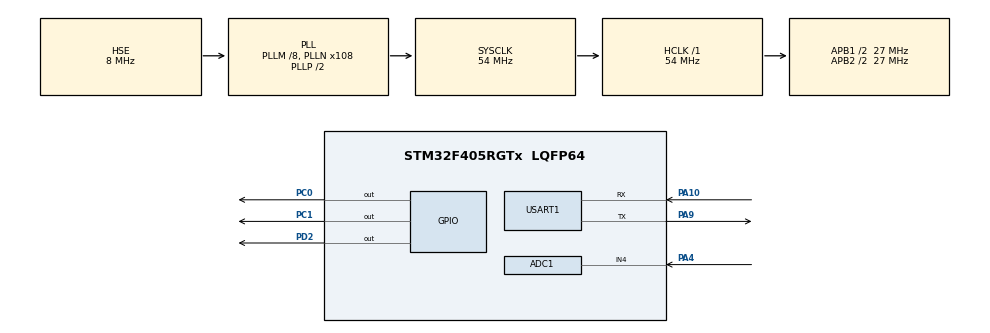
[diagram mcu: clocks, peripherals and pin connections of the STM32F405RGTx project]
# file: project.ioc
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ADC1.Channel-0\#ChannelRegularConversion=ADC_CHANNEL_4
ADC1.ContinuousConvMode=ENABLE
ADC1.DMAContinuousRequests=ENABLE
ADC1.NbrOfConversionFlag=1
ADC1.Rank-0\#ChannelRegularConversion=1
ADC1.SamplingTime-0\#ChannelRegularConversion=ADC_SAMPLETIME_112CYCLES
ADC1.master=1
Dma.ADC1.0.Direction=DMA_PERIPH_TO_MEMORY
Dma.ADC1.0.FIFOMode=DMA_FIFOMODE_DISABLE
Dma.ADC1.0.Instance=DMA2_Stream0
Dma.ADC1.0.MemDataAlignment=DMA_MDATAALIGN_HALFWORD
Dma.ADC1.0.MemInc=DMA_MINC_ENABLE
Dma.ADC1.0.Mode=DMA_CIRCULAR
Dma.ADC1.0.PeriphDataAlignment=DMA_PDATAALIGN_HALFWORD
Dma.ADC1.0.PeriphInc=DMA_PINC_DISABLE
Dma.ADC1.0.Priority=DMA_PRIORITY_HIGH
Dma.Request0=ADC1
Mcu.Family=STM32F4
Mcu.Name=STM32F405RGTx
Mcu.Package=LQFP64
NVIC.DMA2_Stream0_IRQn=true\:1\:0\:true\:false\:true
NVIC.PriorityGroup=NVIC_PRIORITYGROUP_4
PA10.Mode=Asynchronous
PA10.Signal=USART1_RX
PA4.Signal=ADCx_IN4
PA9.Mode=Asynchronous
PA9.Signal=USART1_TX
PC0.Signal=GPIO_Output
PC1.Signal=GPIO_Output
PD2.Signal=GPIO_Output
PH0-OSC_IN.Mode=HSE-External-Oscillator
PH0-OSC_IN.Signal=RCC_OSC_IN
PH1-OSC_OUT.Mode=HSE-External-Oscillator
PH1-OSC_OUT.Signal=RCC_OSC_OUT
ProjectManager.HeapSize=0x200
ProjectManager.StackSize=0x400
ProjectManager.TargetToolchain=MDK-ARM V5
RCC.48MHZClocksFreq_Value=27000000
RCC.AHBFreq_Value=54000000
RCC.APB1CLKDivider=RCC_HCLK_DIV2
RCC.APB1Freq_Value=27000000
RCC.APB1TimFreq_Value=54000000
RCC.APB2CLKDivider=RCC_HCLK_DIV2
RCC.APB2Freq_Value=27000000
RCC.APB2TimFreq_Value=54000000
RCC.CortexFreq_Value=54000000
RCC.HCLKFreq_Value=54000000
RCC.HSE_VALUE=8000000
RCC.HSI_VALUE=16000000
RCC.LSE_VALUE=32768
RCC.PLLM=8
RCC.PLLN=108
RCC.PLLSourceVirtual=RCC_PLLSOURCE_HSE
RCC.SYSCLKFreq_VALUE=54000000
RCC.SYSCLKSource=RCC_SYSCLKSOURCE_PLLCLK
RCC.VCOOutputFreq_Value=108000000
SH.ADCx_IN4.0=ADC1_IN4,IN4
board=project

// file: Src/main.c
/**
  ******************************************************************************
  * File Name          : main.c
  * Description        : Main program body
  ******************************************************************************
  *
  * COPYRIGHT(c) 2018 STMicroelectronics
  *
  * Redistribution and use in source and binary forms, with or without modification,
  * are permitted provided that the following conditions are met:
  *   1. Redistributions of source code must retain the above copyright notice,
  *      this list of conditions and the following disclaimer.
  *   2. Redistributions in binary form must reproduce the above copyright notice,
  *      this list of conditions and the following disclaimer in the documentation
  *      and/or other materials provided with the distribution.
  *   3. Neither the name of STMicroelectronics nor the names of its contributors
  *      may be used to endorse or promote products derived from this software
  *      without specific prior written permission.
  *
  * THIS SOFTWARE IS PROVIDED BY THE COPYRIGHT HOLDERS AND CONTRIBUTORS "AS IS"
  * AND ANY EXPRESS OR IMPLIED WARRANTIES, INCLUDING, BUT NOT LIMITED TO, THE
  * IMPLIED WARRANTIES OF MERCHANTABILITY AND FITNESS FOR A PARTICULAR PURPOSE ARE
  * DISCLAIMED. IN NO EVENT SHALL THE COPYRIGHT HOLDER OR CONTRIBUTORS BE LIABLE
  * FOR ANY DIRECT, INDIRECT, INCIDENTAL, SPECIAL, EXEMPLARY, OR CONSEQUENTIAL
  * DAMAGES (INCLUDING, BUT NOT LIMITED TO, PROCUREMENT OF SUBSTITUTE GOODS OR
  * SERVICES; LOSS OF USE, DATA, OR PROFITS; OR BUSINESS INTERRUPTION) HOWEVER
  * CAUSED AND ON ANY THEORY OF LIABILITY, WHETHER IN CONTRACT, STRICT LIABILITY,
  * OR TORT (INCLUDING NEGLIGENCE OR OTHERWISE) ARISING IN ANY WAY OUT OF THE USE
  * OF THIS SOFTWARE, EVEN IF ADVISED OF THE POSSIBILITY OF SUCH DAMAGE.
  *
  ******************************************************************************
  */
#include "stm32f4xx_hal.h"
#include "adc.h"
#include "dma.h"
#include "usart.h"
#include "gpio.h"
#include "sort.h"

/* USER CODE BEGIN PV */
/* Private variables ---------------------------------------------------------*/

/* USER CODE END PV */

void SystemClock_Config(void);
void Error_Handler(void);

/* USER CODE BEGIN PFP */
/* Private function prototypes -----------------------------------------------*/

/* USER CODE END PFP */

int main(void)
{

  /* USER CODE BEGIN 1 */
  uint16_t ADC_Buffer[16];
  uint8_t i;
  double ADC_Value;
  /* USER CODE END 1 */

  /* MCU Configuration----------------------------------------------------------*/

  /* Reset of all peripherals, Initializes the Flash interface and the Systick. */
  HAL_Init();

  /* Configure the system clock */
  SystemClock_Config();

  /* Initialize all configured peripherals */
  MX_GPIO_Init();
  MX_DMA_Init();
  MX_ADC1_Init();
  MX_USART1_UART_Init();

  /* USER CODE BEGIN 2 */
    //ADCDMA��ʼ��
   if(HAL_ADC_Start_DMA(&hadc1,(uint32_t*)ADC_Buffer,16)!=HAL_OK)
       Error_Handler();
  /* USER CODE END 2 */

  /* Infinite loop */
  while (1)
  {
        HAL_Delay(1);               //延时1ms
        HAL_ADC_Stop_DMA(&hadc1);           //停止DMA
		QuickSort(ADC_Buffer,0,15);                  //快速排序
        for(i=3;i<13;i++)
             ADC_Value += ADC_Buffer[i];
         ADC_Value = (double) (ADC_Value / 10);
        ADC_Value  = ADC_Value*3.3/4096;
        printf("%.4f\r\n",ADC_Value);
        HAL_Delay(10);
        if(HAL_ADC_Start_DMA(&hadc1,(uint32_t*)ADC_Buffer,16)!=HAL_OK)
                Error_Handler();
//        if(HAL_ADC_Start_DMA(&hadc1,(uint32_t*)ADC_Buffer,16)!=HAL_OK)
//            Error_Handler();
  }

}

/** System Clock Configuration
*/
void SystemClock_Config(void)
{

  RCC_OscInitTypeDef RCC_OscInitStruct;
  RCC_ClkInitTypeDef RCC_ClkInitStruct;

  __HAL_RCC_PWR_CLK_ENABLE();

  __HAL_PWR_VOLTAGESCALING_CONFIG(PWR_REGULATOR_VOLTAGE_SCALE1);

  RCC_OscInitStruct.OscillatorType = RCC_OSCILLATORTYPE_HSE;
  RCC_OscInitStruct.HSEState = RCC_HSE_ON;
  RCC_OscInitStruct.PLL.PLLState = RCC_PLL_ON;
  RCC_OscInitStruct.PLL.PLLSource = RCC_PLLSOURCE_HSE;
  RCC_OscInitStruct.PLL.PLLM = 8;
  RCC_OscInitStruct.PLL.PLLN = 108;
  RCC_OscInitStruct.PLL.PLLP = RCC_PLLP_DIV2;
  RCC_OscInitStruct.PLL.PLLQ = 4;
  if (HAL_RCC_OscConfig(&RCC_OscInitStruct) != HAL_OK)
  {
    Error_Handler();
  }

  RCC_ClkInitStruct.ClockType = RCC_CLOCKTYPE_HCLK|RCC_CLOCKTYPE_SYSCLK
                              |RCC_CLOCKTYPE_PCLK1|RCC_CLOCKTYPE_PCLK2;
  RCC_ClkInitStruct.SYSCLKSource = RCC_SYSCLKSOURCE_PLLCLK;
  RCC_ClkInitStruct.AHBCLKDivider = RCC_SYSCLK_DIV1;
  RCC_ClkInitStruct.APB1CLKDivider = RCC_HCLK_DIV2;
  RCC_ClkInitStruct.APB2CLKDivider = RCC_HCLK_DIV2;
  if (HAL_RCC_ClockConfig(&RCC_ClkInitStruct, FLASH_LATENCY_1) != HAL_OK)
  {
    Error_Handler();
  }

  HAL_SYSTICK_Config(HAL_RCC_GetHCLKFreq()/1000);

  HAL_SYSTICK_CLKSourceConfig(SYSTICK_CLKSOURCE_HCLK);

  /* SysTick_IRQn interrupt configuration */
  HAL_NVIC_SetPriority(SysTick_IRQn, 0, 0);
}

void Error_Handler(void)
{
  while(1)
  {
  }
}

/************************ (C) COPYRIGHT STMicroelectronics *****END OF FILE****/
